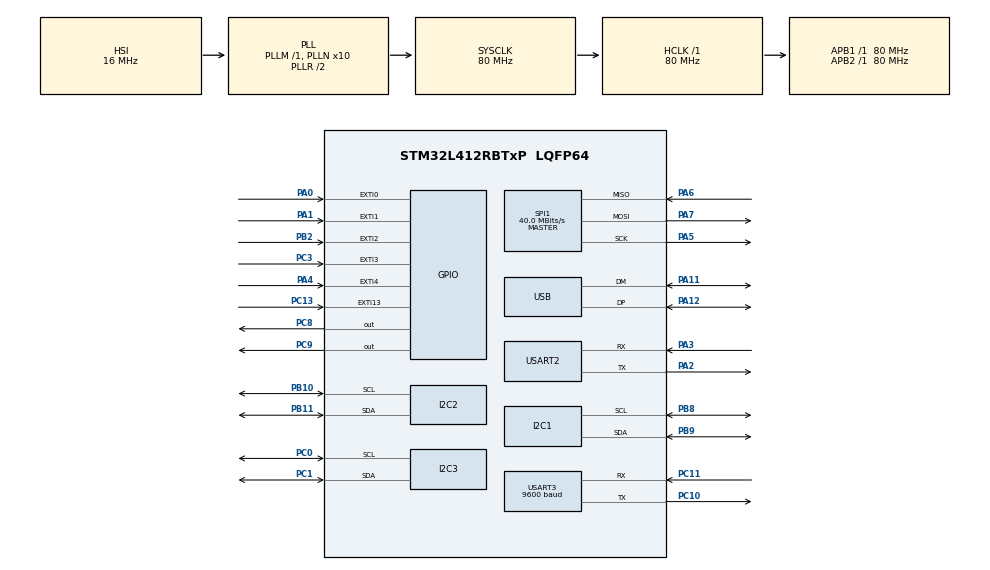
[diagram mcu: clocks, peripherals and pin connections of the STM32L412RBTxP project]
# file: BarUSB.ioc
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Dma.Request0=USART3_RX
Dma.Request1=USART3_TX
Dma.USART3_RX.0.Direction=DMA_PERIPH_TO_MEMORY
Dma.USART3_RX.0.Instance=DMA1_Channel3
Dma.USART3_RX.0.MemDataAlignment=DMA_MDATAALIGN_BYTE
Dma.USART3_RX.0.MemInc=DMA_MINC_ENABLE
Dma.USART3_RX.0.Mode=DMA_CIRCULAR
Dma.USART3_RX.0.PeriphDataAlignment=DMA_PDATAALIGN_BYTE
Dma.USART3_RX.0.PeriphInc=DMA_PINC_DISABLE
Dma.USART3_RX.0.Priority=DMA_PRIORITY_LOW
Dma.USART3_TX.1.Direction=DMA_MEMORY_TO_PERIPH
Dma.USART3_TX.1.Instance=DMA1_Channel2
Dma.USART3_TX.1.MemDataAlignment=DMA_MDATAALIGN_BYTE
Dma.USART3_TX.1.MemInc=DMA_MINC_ENABLE
Dma.USART3_TX.1.Mode=DMA_NORMAL
Dma.USART3_TX.1.PeriphDataAlignment=DMA_PDATAALIGN_BYTE
Dma.USART3_TX.1.PeriphInc=DMA_PINC_DISABLE
Dma.USART3_TX.1.Priority=DMA_PRIORITY_LOW
I2C1.Timing=0x10909CEC
I2C2.Timing=0x10909CEC
I2C3.CustomTiming=Disabled
I2C3.Timing=0x10909CEC
Mcu.Family=STM32L4
Mcu.Name=STM32L412RBTxP
Mcu.Package=LQFP64
NVIC.DMA1_Channel2_IRQn=true\:0\:0\:false\:false\:true\:false\:true\:true
NVIC.DMA1_Channel3_IRQn=true\:0\:0\:false\:false\:true\:false\:true\:true
NVIC.EXTI15_10_IRQn=true\:0\:0\:false\:false\:true\:true\:true\:true
NVIC.PriorityGroup=NVIC_PRIORITYGROUP_4
NVIC.USB_IRQn=true\:0\:0\:false\:false\:true\:false\:true\:true
PA0.Signal=GPXTI0
PA1.Signal=GPXTI1
PA10.Signal=USART1_RX
PA11.Mode=Device
PA11.Signal=USB_DM
PA12.Mode=Device
PA12.Signal=USB_DP
PA2.Mode=Asynchronous
PA2.Signal=USART2_TX
PA3.Mode=Asynchronous
PA3.Signal=USART2_RX
PA4.Signal=GPXTI4
PA5.Mode=Full_Duplex_Master
PA5.Signal=SPI1_SCK
PA6.Mode=Full_Duplex_Master
PA6.Signal=SPI1_MISO
PA7.Mode=Full_Duplex_Master
PA7.Signal=SPI1_MOSI
PA9.Signal=USART1_TX
PB10.Mode=I2C
PB10.Signal=I2C2_SCL
PB11.Mode=I2C
PB11.Signal=I2C2_SDA
PB13.Signal=SPI2_SCK
PB14.Signal=SPI2_MISO
PB15.Signal=SPI2_MOSI
PB2.Signal=GPXTI2
PB8.Mode=I2C
PB8.Signal=I2C1_SCL
PB9.Mode=I2C
PB9.Signal=I2C1_SDA
PC0.Mode=I2C
PC0.Signal=I2C3_SCL
PC1.Mode=I2C
PC1.Signal=I2C3_SDA
PC10.Mode=Asynchronous
PC10.Signal=USART3_TX
PC11.Mode=Asynchronous
PC11.Signal=USART3_RX
PC13.GPIO_ModeDefaultEXTI=GPIO_MODE_IT_FALLING
PC13.Signal=GPXTI13
PC14-OSC32_IN\ (PC14).Mode=LSE-External-Oscillator
PC14-OSC32_IN\ (PC14).Signal=RCC_OSC32_IN
PC15-OSC32_OUT\ (PC15).Mode=LSE-External-Oscillator
PC15-OSC32_OUT\ (PC15).Signal=RCC_OSC32_OUT
PC3.Signal=GPXTI3
PC8.Signal=GPIO_Output
PC9.Signal=GPIO_Output
PH0-OSC_IN\ (PH0).Signal=RCC_OSC_IN
PH1-OSC_OUT\ (PH1).Signal=RCC_OSC_OUT
ProjectManager.HeapSize=0x200
ProjectManager.StackSize=0x400
ProjectManager.TargetToolchain=STM32CubeIDE
RCC.ADCFreq_Value=80000000
RCC.AHBFreq_Value=80000000
RCC.APB1Freq_Value=80000000
RCC.APB1TimFreq_Value=80000000
RCC.APB2Freq_Value=80000000
RCC.APB2TimFreq_Value=80000000
RCC.CortexFreq_Value=80000000
RCC.HCLKFreq_Value=80000000
RCC.HSE_VALUE=8000000
RCC.HSI48_VALUE=48000000
RCC.HSI_VALUE=16000000
RCC.MSIClockRange=RCC_MSIRANGE_11
RCC.MSI_VALUE=48000000
RCC.PLLN=10
RCC.PLLSourceVirtual=RCC_PLLSOURCE_HSI
RCC.SYSCLKFreq_VALUE=80000000
RCC.SYSCLKSource=RCC_SYSCLKSOURCE_PLLCLK
RCC.USBFreq_Value=48000000
RCC.VCOOutputFreq_Value=160000000
SPI1.CalculateBaudRate=40.0 MBits/s
SPI1.Direction=SPI_DIRECTION_2LINES
SPI1.Mode=SPI_MODE_MASTER
SPI1.VirtualType=VM_MASTER
TIM2.Prescaler=4-1
USART2.VirtualMode-Asynchronous=VM_ASYNC
USART3.BaudRate=9600
USART3.VirtualMode-Asynchronous=VM_ASYNC
USB_DEVICE.CLASS_NAME_FS=CDC
USB_DEVICE.VirtualMode=Cdc
USB_DEVICE.VirtualModeFS=Cdc_FS
VP_TIM2_VS_ClockSourceINT.Mode=Internal
VP_USB_DEVICE_VS_USB_DEVICE_CDC_FS.Mode=CDC_FS
board=custom

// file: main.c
/* USER CODE BEGIN Header */
/**
  ******************************************************************************
  * @file           : main.c
  * @brief          : Main program body
  ******************************************************************************
  * @attention
  *
  * Copyright (c) 2023 STMicroelectronics.
  * All rights reserved.
  *
  * This software is licensed under terms that can be found in the LICENSE file
  * in the root directory of this software component.
  * If no LICENSE file comes with this software, it is provided AS-IS.
  *
  ******************************************************************************
  */
/* USER CODE END Header */
#include "main.h"
//ADDED IN
#include "usb_device.h"
#include "usbd_cdc_if.h"
#include "dps310.h"
//

I2C_HandleTypeDef hi2c1;
I2C_HandleTypeDef hi2c2;
I2C_HandleTypeDef hi2c3;

SPI_HandleTypeDef hspi1;

TIM_HandleTypeDef htim2;

UART_HandleTypeDef huart2;
UART_HandleTypeDef huart3;
DMA_HandleTypeDef hdma_usart3_rx;
DMA_HandleTypeDef hdma_usart3_tx;

void SystemClock_Config(void);
static void MX_GPIO_Init(void);
static void MX_DMA_Init(void);
static void MX_SPI1_Init(void);
static void MX_I2C1_Init(void);
static void MX_USART3_UART_Init(void);
static void MX_I2C3_Init(void);
static void MX_USART2_UART_Init(void);
static void MX_I2C2_Init(void);
static void MX_TIM2_Init(void);

//ADDED IN
float altdif = 0;
//

int main(void)
{

  /* MCU Configuration--------------------------------------------------------*/

  /* Reset of all peripherals, Initializes the Flash interface and the Systick. */
  HAL_Init();

  /* Configure the system clock */
  SystemClock_Config();

  /* Initialize all configured peripherals */
  MX_GPIO_Init();
  MX_DMA_Init();
  MX_SPI1_Init();
  MX_I2C1_Init();
  MX_USART3_UART_Init();
  MX_I2C3_Init();
  MX_USART2_UART_Init();
  MX_I2C2_Init();
  MX_TIM2_Init();
  MX_USB_DEVICE_Init();
  /* USER CODE BEGIN 2 */

  //ADDED IN
  DPS310_Start();
  //

  /* USER CODE END 2 */

  /* Infinite loop */
  while (1)
  {
  }
}

//ADDED IN
void HAL_GPIO_EXTI_Callback(uint16_t GPIO_Pin)
{
    if(GPIO_Pin == GPIO_PIN_13) // If The INT Source Is EXTI Line13
    {
    	altdif = DPS310_GetPress();
    	char buff[127];
    	snprintf(buff, 127, "Altitude Difference = %f\r\n", altdif);
    	CDC_Transmit_FS((uint8_t *)buff, strlen(buff));
    }
}
//

void SystemClock_Config(void)
{
  RCC_OscInitTypeDef RCC_OscInitStruct = {0};
  RCC_ClkInitTypeDef RCC_ClkInitStruct = {0};

  /** Configure the main internal regulator output voltage
  */
  if (HAL_PWREx_ControlVoltageScaling(PWR_REGULATOR_VOLTAGE_SCALE1) != HAL_OK)
  {
    Error_Handler();
  }

  /** Configure LSE Drive Capability
  */
  HAL_PWR_EnableBkUpAccess();
  __HAL_RCC_LSEDRIVE_CONFIG(RCC_LSEDRIVE_LOW);

  /** Initializes the RCC Oscillators according to the specified parameters
  * in the RCC_OscInitTypeDef structure.
  */
  RCC_OscInitStruct.OscillatorType = RCC_OSCILLATORTYPE_HSI|RCC_OSCILLATORTYPE_LSE
                              |RCC_OSCILLATORTYPE_MSI;
  RCC_OscInitStruct.LSEState = RCC_LSE_ON;
  RCC_OscInitStruct.HSIState = RCC_HSI_ON;
  RCC_OscInitStruct.HSICalibrationValue = RCC_HSICALIBRATION_DEFAULT;
  RCC_OscInitStruct.MSIState = RCC_MSI_ON;
  RCC_OscInitStruct.MSICalibrationValue = 0;
  RCC_OscInitStruct.MSIClockRange = RCC_MSIRANGE_11;
  RCC_OscInitStruct.PLL.PLLState = RCC_PLL_ON;
  RCC_OscInitStruct.PLL.PLLSource = RCC_PLLSOURCE_HSI;
  RCC_OscInitStruct.PLL.PLLM = 1;
  RCC_OscInitStruct.PLL.PLLN = 10;
  RCC_OscInitStruct.PLL.PLLQ = RCC_PLLQ_DIV2;
  RCC_OscInitStruct.PLL.PLLR = RCC_PLLR_DIV2;
  if (HAL_RCC_OscConfig(&RCC_OscInitStruct) != HAL_OK)
  {
    Error_Handler();
  }

  /** Initializes the CPU, AHB and APB buses clocks
  */
  RCC_ClkInitStruct.ClockType = RCC_CLOCKTYPE_HCLK|RCC_CLOCKTYPE_SYSCLK
                              |RCC_CLOCKTYPE_PCLK1|RCC_CLOCKTYPE_PCLK2;
  RCC_ClkInitStruct.SYSCLKSource = RCC_SYSCLKSOURCE_PLLCLK;
  RCC_ClkInitStruct.AHBCLKDivider = RCC_SYSCLK_DIV1;
  RCC_ClkInitStruct.APB1CLKDivider = RCC_HCLK_DIV1;
  RCC_ClkInitStruct.APB2CLKDivider = RCC_HCLK_DIV1;

  if (HAL_RCC_ClockConfig(&RCC_ClkInitStruct, FLASH_LATENCY_4) != HAL_OK)
  {
    Error_Handler();
  }

  /** Enable MSI Auto calibration
  */
  HAL_RCCEx_EnableMSIPLLMode();
}

static void MX_I2C1_Init(void)
{

  hi2c1.Instance = I2C1;
  hi2c1.Init.Timing = 0x10909CEC;
  hi2c1.Init.OwnAddress1 = 0;
  hi2c1.Init.AddressingMode = I2C_ADDRESSINGMODE_7BIT;
  hi2c1.Init.DualAddressMode = I2C_DUALADDRESS_DISABLE;
  hi2c1.Init.OwnAddress2 = 0;
  hi2c1.Init.OwnAddress2Masks = I2C_OA2_NOMASK;
  hi2c1.Init.GeneralCallMode = I2C_GENERALCALL_DISABLE;
  hi2c1.Init.NoStretchMode = I2C_NOSTRETCH_DISABLE;
  if (HAL_I2C_Init(&hi2c1) != HAL_OK)
  {
    Error_Handler();
  }

  /** Configure Analogue filter
  */
  if (HAL_I2CEx_ConfigAnalogFilter(&hi2c1, I2C_ANALOGFILTER_ENABLE) != HAL_OK)
  {
    Error_Handler();
  }

  /** Configure Digital filter
  */
  if (HAL_I2CEx_ConfigDigitalFilter(&hi2c1, 0) != HAL_OK)
  {
    Error_Handler();
  }

}

static void MX_I2C2_Init(void)
{

  hi2c2.Instance = I2C2;
  hi2c2.Init.Timing = 0x10909CEC;
  hi2c2.Init.OwnAddress1 = 0;
  hi2c2.Init.AddressingMode = I2C_ADDRESSINGMODE_7BIT;
  hi2c2.Init.DualAddressMode = I2C_DUALADDRESS_DISABLE;
  hi2c2.Init.OwnAddress2 = 0;
  hi2c2.Init.OwnAddress2Masks = I2C_OA2_NOMASK;
  hi2c2.Init.GeneralCallMode = I2C_GENERALCALL_DISABLE;
  hi2c2.Init.NoStretchMode = I2C_NOSTRETCH_DISABLE;
  if (HAL_I2C_Init(&hi2c2) != HAL_OK)
  {
    Error_Handler();
  }

  /** Configure Analogue filter
  */
  if (HAL_I2CEx_ConfigAnalogFilter(&hi2c2, I2C_ANALOGFILTER_ENABLE) != HAL_OK)
  {
    Error_Handler();
  }

  /** Configure Digital filter
  */
  if (HAL_I2CEx_ConfigDigitalFilter(&hi2c2, 0) != HAL_OK)
  {
    Error_Handler();
  }

}

static void MX_I2C3_Init(void)
{

  hi2c3.Instance = I2C3;
  hi2c3.Init.Timing = 0x10909CEC;
  hi2c3.Init.OwnAddress1 = 0;
  hi2c3.Init.AddressingMode = I2C_ADDRESSINGMODE_7BIT;
  hi2c3.Init.DualAddressMode = I2C_DUALADDRESS_DISABLE;
  hi2c3.Init.OwnAddress2 = 0;
  hi2c3.Init.OwnAddress2Masks = I2C_OA2_NOMASK;
  hi2c3.Init.GeneralCallMode = I2C_GENERALCALL_DISABLE;
  hi2c3.Init.NoStretchMode = I2C_NOSTRETCH_DISABLE;
  if (HAL_I2C_Init(&hi2c3) != HAL_OK)
  {
    Error_Handler();
  }

  /** Configure Analogue filter
  */
  if (HAL_I2CEx_ConfigAnalogFilter(&hi2c3, I2C_ANALOGFILTER_ENABLE) != HAL_OK)
  {
    Error_Handler();
  }

  /** Configure Digital filter
  */
  if (HAL_I2CEx_ConfigDigitalFilter(&hi2c3, 0) != HAL_OK)
  {
    Error_Handler();
  }

}

static void MX_SPI1_Init(void)
{

  /* SPI1 parameter configuration*/
  hspi1.Instance = SPI1;
  hspi1.Init.Mode = SPI_MODE_MASTER;
  hspi1.Init.Direction = SPI_DIRECTION_2LINES;
  hspi1.Init.DataSize = SPI_DATASIZE_4BIT;
  hspi1.Init.CLKPolarity = SPI_POLARITY_LOW;
  hspi1.Init.CLKPhase = SPI_PHASE_1EDGE;
  hspi1.Init.NSS = SPI_NSS_SOFT;
  hspi1.Init.BaudRatePrescaler = SPI_BAUDRATEPRESCALER_2;
  hspi1.Init.FirstBit = SPI_FIRSTBIT_MSB;
  hspi1.Init.TIMode = SPI_TIMODE_DISABLE;
  hspi1.Init.CRCCalculation = SPI_CRCCALCULATION_DISABLE;
  hspi1.Init.CRCPolynomial = 7;
  hspi1.Init.CRCLength = SPI_CRC_LENGTH_DATASIZE;
  hspi1.Init.NSSPMode = SPI_NSS_PULSE_ENABLE;
  if (HAL_SPI_Init(&hspi1) != HAL_OK)
  {
    Error_Handler();
  }

}

static void MX_TIM2_Init(void)
{

  TIM_ClockConfigTypeDef sClockSourceConfig = {0};
  TIM_MasterConfigTypeDef sMasterConfig = {0};

  htim2.Instance = TIM2;
  htim2.Init.Prescaler = 4-1;
  htim2.Init.CounterMode = TIM_COUNTERMODE_UP;
  htim2.Init.Period = 4294967295;
  htim2.Init.ClockDivision = TIM_CLOCKDIVISION_DIV1;
  htim2.Init.AutoReloadPreload = TIM_AUTORELOAD_PRELOAD_DISABLE;
  if (HAL_TIM_Base_Init(&htim2) != HAL_OK)
  {
    Error_Handler();
  }
  sClockSourceConfig.ClockSource = TIM_CLOCKSOURCE_INTERNAL;
  if (HAL_TIM_ConfigClockSource(&htim2, &sClockSourceConfig) != HAL_OK)
  {
    Error_Handler();
  }
  sMasterConfig.MasterOutputTrigger = TIM_TRGO_RESET;
  sMasterConfig.MasterSlaveMode = TIM_MASTERSLAVEMODE_DISABLE;
  if (HAL_TIMEx_MasterConfigSynchronization(&htim2, &sMasterConfig) != HAL_OK)
  {
    Error_Handler();
  }

}

static void MX_USART2_UART_Init(void)
{

  huart2.Instance = USART2;
  huart2.Init.BaudRate = 115200;
  huart2.Init.WordLength = UART_WORDLENGTH_8B;
  huart2.Init.StopBits = UART_STOPBITS_1;
  huart2.Init.Parity = UART_PARITY_NONE;
  huart2.Init.Mode = UART_MODE_TX_RX;
  huart2.Init.HwFlowCtl = UART_HWCONTROL_NONE;
  huart2.Init.OverSampling = UART_OVERSAMPLING_16;
  huart2.Init.OneBitSampling = UART_ONE_BIT_SAMPLE_DISABLE;
  huart2.AdvancedInit.AdvFeatureInit = UART_ADVFEATURE_NO_INIT;
  if (HAL_UART_Init(&huart2) != HAL_OK)
  {
    Error_Handler();
  }

}

static void MX_USART3_UART_Init(void)
{

  huart3.Instance = USART3;
  huart3.Init.BaudRate = 9600;
  huart3.Init.WordLength = UART_WORDLENGTH_8B;
  huart3.Init.StopBits = UART_STOPBITS_1;
  huart3.Init.Parity = UART_PARITY_NONE;
  huart3.Init.Mode = UART_MODE_TX_RX;
  huart3.Init.HwFlowCtl = UART_HWCONTROL_NONE;
  huart3.Init.OverSampling = UART_OVERSAMPLING_16;
  huart3.Init.OneBitSampling = UART_ONE_BIT_SAMPLE_DISABLE;
  huart3.AdvancedInit.AdvFeatureInit = UART_ADVFEATURE_NO_INIT;
  if (HAL_UART_Init(&huart3) != HAL_OK)
  {
    Error_Handler();
  }

}

static void MX_DMA_Init(void)
{

  /* DMA controller clock enable */
  __HAL_RCC_DMA1_CLK_ENABLE();

  /* DMA interrupt init */
  /* DMA1_Channel2_IRQn interrupt configuration */
  HAL_NVIC_SetPriority(DMA1_Channel2_IRQn, 0, 0);
  HAL_NVIC_EnableIRQ(DMA1_Channel2_IRQn);
  /* DMA1_Channel3_IRQn interrupt configuration */
  HAL_NVIC_SetPriority(DMA1_Channel3_IRQn, 0, 0);
  HAL_NVIC_EnableIRQ(DMA1_Channel3_IRQn);

}

static void MX_GPIO_Init(void)
{
  GPIO_InitTypeDef GPIO_InitStruct = {0};

  /* GPIO Ports Clock Enable */
  __HAL_RCC_GPIOC_CLK_ENABLE();
  __HAL_RCC_GPIOH_CLK_ENABLE();
  __HAL_RCC_GPIOA_CLK_ENABLE();
  __HAL_RCC_GPIOB_CLK_ENABLE();

  /*Configure GPIO pin Output Level */
  HAL_GPIO_WritePin(GPIOC, GPIO_PIN_8|GPIO_PIN_9, GPIO_PIN_RESET);

  /*Configure GPIO pin : PC13 */
  GPIO_InitStruct.Pin = GPIO_PIN_13;
  GPIO_InitStruct.Mode = GPIO_MODE_IT_FALLING;
  GPIO_InitStruct.Pull = GPIO_NOPULL;
  HAL_GPIO_Init(GPIOC, &GPIO_InitStruct);

  /*Configure GPIO pin : PC3 */
  GPIO_InitStruct.Pin = GPIO_PIN_3;
  GPIO_InitStruct.Mode = GPIO_MODE_IT_RISING;
  GPIO_InitStruct.Pull = GPIO_NOPULL;
  HAL_GPIO_Init(GPIOC, &GPIO_InitStruct);

  /*Configure GPIO pins : PA0 PA1 PA4 */
  GPIO_InitStruct.Pin = GPIO_PIN_0|GPIO_PIN_1|GPIO_PIN_4;
  GPIO_InitStruct.Mode = GPIO_MODE_IT_RISING;
  GPIO_InitStruct.Pull = GPIO_NOPULL;
  HAL_GPIO_Init(GPIOA, &GPIO_InitStruct);

  /*Configure GPIO pin : PB2 */
  GPIO_InitStruct.Pin = GPIO_PIN_2;
  GPIO_InitStruct.Mode = GPIO_MODE_IT_RISING;
  GPIO_InitStruct.Pull = GPIO_NOPULL;
  HAL_GPIO_Init(GPIOB, &GPIO_InitStruct);

  /*Configure GPIO pins : PB13 PB14 PB15 */
  GPIO_InitStruct.Pin = GPIO_PIN_13|GPIO_PIN_14|GPIO_PIN_15;
  GPIO_InitStruct.Mode = GPIO_MODE_AF_PP;
  GPIO_InitStruct.Pull = GPIO_NOPULL;
  GPIO_InitStruct.Speed = GPIO_SPEED_FREQ_VERY_HIGH;
  GPIO_InitStruct.Alternate = GPIO_AF5_SPI2;
  HAL_GPIO_Init(GPIOB, &GPIO_InitStruct);

  /*Configure GPIO pins : PC8 PC9 */
  GPIO_InitStruct.Pin = GPIO_PIN_8|GPIO_PIN_9;
  GPIO_InitStruct.Mode = GPIO_MODE_OUTPUT_PP;
  GPIO_InitStruct.Pull = GPIO_NOPULL;
  GPIO_InitStruct.Speed = GPIO_SPEED_FREQ_LOW;
  HAL_GPIO_Init(GPIOC, &GPIO_InitStruct);

  /*Configure GPIO pins : PA9 PA10 */
  GPIO_InitStruct.Pin = GPIO_PIN_9|GPIO_PIN_10;
  GPIO_InitStruct.Mode = GPIO_MODE_AF_PP;
  GPIO_InitStruct.Pull = GPIO_NOPULL;
  GPIO_InitStruct.Speed = GPIO_SPEED_FREQ_VERY_HIGH;
  GPIO_InitStruct.Alternate = GPIO_AF7_USART1;
  HAL_GPIO_Init(GPIOA, &GPIO_InitStruct);

  /* EXTI interrupt init*/
  HAL_NVIC_SetPriority(EXTI15_10_IRQn, 0, 0);
  HAL_NVIC_EnableIRQ(EXTI15_10_IRQn);

}

void Error_Handler(void)
{
  __disable_irq();
  while (1)
  {
  }
}
